AUTOSAR XML (schema 00049)
# Copyright (c) 2018 Vector Informatik GmbH.
standard types defined: boolean, uint8
package /VehicleProject
  system System
package /TP
  lin tp config LIN00: communication-cluster=LIN00
    tp address TA_0x0001: tp-address=1
    tp address TA_0x0006: tp-address=6
    tp address TA_0x007E: tp-address=126
    tp-connections:
      data-pdu=MasterReq_Tp, lin-tp-n-sdu=MasterReq, multicast=TA_0x007E, receiver=[TN_0x0001_DWF_Left, TN_0x0006_DWF_Right], transmitter=TN_Master
      data-pdu=SlaveResp_Tp, flow-control=MasterReq_Tp, lin-tp-n-sdu=SlaveResp_DWF_Left, receiver=TN_Master, transmitter=TN_0x0001_DWF_Left
      data-pdu=SlaveResp_Tp, flow-control=MasterReq_Tp, lin-tp-n-sdu=SlaveResp_DWF_Right, receiver=TN_Master, transmitter=TN_0x0006_DWF_Right
      data-pdu=MasterReq_Tp, flow-control=SlaveResp_Tp, lin-tp-n-sdu=MasterReq_DWF_Left, receiver=TN_0x0001_DWF_Left, transmitter=TN_Master
      data-pdu=MasterReq_Tp, flow-control=SlaveResp_Tp, lin-tp-n-sdu=MasterReq_DWF_Right, receiver=TN_0x0006_DWF_Right, transmitter=TN_Master
    lin tp node TN_0x0001_DWF_Left: connector=DWF_Left/CN_LIN00, tp-address=TA_0x0001
    lin tp node TN_0x0006_DWF_Right: connector=DWF_Right/CN_LIN00, tp-address=TA_0x0006
    lin tp node TN_Master: connector=GWI/CN_LIN00
package /Cluster
  lin cluster LIN00: baudrate=19200, protocol-name=LIN, protocol-version=LIN22  # Door_minimal | /*************************************************************************************/ // // Description: LIN Description file created using Vector's DaVinci Network Designer // Created: 12 Oct 2007 10:43:53 // Author: Vector Informatik GmbH // Version: 0.1 // /*************************************************************************************/
    lin physical channel CHNL: comm-connectors=[DWF_Left/CN_LIN00, DWF_Right/CN_LIN00, GWI/CN_LIN00]
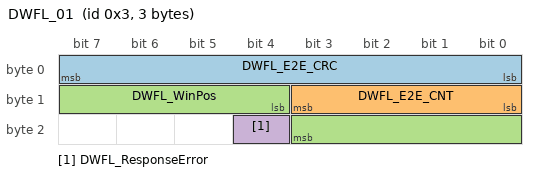
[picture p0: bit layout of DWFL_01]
      frame DWFL_01: id 0x3, from DWF_Left, to GWI, frame-length=3, lin-checksum=ENHANCED
        pdu DWFL_01: length=3, unused-bit-pattern=255
          signal DWFL_E2E_CRC: start 0, 8 bit, little-endian, i-signal-type=PRIMITIVE, init-value=0, base-type=uint8, compu {identical}, range raw 0..255, to GWI
          signal DWFL_E2E_CNT: start 8, 4 bit, little-endian, i-signal-type=PRIMITIVE, init-value=0, base-type=uint8, compu {identical}, range raw 0..15, to GWI
          signal DWFL_WinPos: start 12, 8 bit, little-endian, i-signal-type=PRIMITIVE, init-value=0, base-type=uint8, compu {identical}, range raw 0..255, to GWI
          signal DWFL_ResponseError: start 20, 1 bit, little-endian, i-signal-type=PRIMITIVE, init-value=0, base-type=boolean, compu {identical}, range raw 0..1, to GWI
          mapping SG_DWFL_E2E_SigGroup: i-signal-group=SG_DWFL_E2E_SigGroup
      frame DWFR_01: id 0x2, from DWF_Right, to GWI, frame-length=2, lin-checksum=ENHANCED
        pdu DWFR_01: length=2, unused-bit-pattern=255
          signal DWFR_WinPos: start 0, 8 bit, little-endian, i-signal-type=PRIMITIVE, init-value=0, base-type=uint8, compu {identical}, range raw 0..255, to GWI
          signal DWFR_ResponseError: start 8, 1 bit, little-endian, i-signal-type=PRIMITIVE, init-value=0, base-type=boolean, compu {identical}, range raw 0..1, to GWI
      frame GWI_01: id 0x1, from GWI, to DWF_Left DWF_Right, frame-length=1, lin-checksum=ENHANCED
        pdu GWI_01: length=1, unused-bit-pattern=255
          signal GWI_FrontWindowsRight: start 0, 2 bit, little-endian, i-signal-type=PRIMITIVE, init-value=1, base-type=uint8, compu {0=Cx0_Down, 1=Cx1_Halt, 2=Cx2_Up}, range raw 0..2, to DWF_Right
          signal GWI_FrontWindowsLeft: start 6, 2 bit, little-endian, i-signal-type=PRIMITIVE, init-value=1, base-type=uint8, compu {0=Cx0_Down, 1=Cx1_Halt, 2=Cx2_Up}, range raw 0..2, to DWF_Left
      frame MasterReq: id 0x3C, from GWI, to DWF_Left DWF_Right, frame-length=8, lin-checksum=CLASSIC
        n pdu MasterReq_Tp: length=8
      frame SlaveResp: id 0x3D, from DWF_Left DWF_Right, to GWI, frame-length=8, lin-checksum=CLASSIC
        n pdu SlaveResp_Tp: length=8
      pdu triggering PT_MasterReq: pdu=MasterReq, from GWI, to DWF_Left DWF_Right
      pdu triggering PT_MasterReq_DWF_Left: pdu=MasterReq_DWF_Left, from GWI, to DWF_Left
      pdu triggering PT_MasterReq_DWF_Right: pdu=MasterReq_DWF_Right, from GWI, to DWF_Right
      pdu triggering PT_SlaveResp_DWF_Left: pdu=SlaveResp_DWF_Left, from DWF_Left, to GWI
      pdu triggering PT_SlaveResp_DWF_Right: pdu=SlaveResp_DWF_Right, from DWF_Right, to GWI
      lin schedule table Table0: run-mode=RUN-CONTINUOUS
        table-entrys:
          delay=0.01, position-in-table=0, frame-triggering=FT_MasterReq
          delay=0.01, position-in-table=1, frame-triggering=FT_SlaveResp
      lin schedule table Table1: run-mode=RUN-CONTINUOUS
        table-entrys:
          delay=0.01, position-in-table=0, frame-triggering=FT_DWFL_01
          delay=0.01, position-in-table=1, frame-triggering=FT_DWFR_01
          delay=0.01, position-in-table=2, frame-triggering=FT_GWI_01
package /ECU
  ecu instance DWF_Left: associated-com-i-pdu-group=[DWF_Left_Rx, DWF_Left_Tx]
    lin slave CT_LIN00: protocol-version=LIN22, assign-nad=true, configured-nad=1, function-id=1, initial-nad=1, lin-error-response=ST_DWFL_ResponseError, nas-timeout=1000, supplier-id=30, variant-id=1
    lin communication connector CN_LIN00: comm-controller=DWF_Left/CT_LIN00, initial-nad=1
  ecu instance DWF_Right: associated-com-i-pdu-group=[DWF_Right_Rx, DWF_Right_Tx]
    lin slave CT_LIN00: protocol-version=LIN21, assign-nad=true, configured-nad=6, function-id=1, initial-nad=6, lin-error-response=ST_DWFR_ResponseError, nas-timeout=1000, supplier-id=30, variant-id=1
    lin communication connector CN_LIN00: comm-controller=DWF_Right/CT_LIN00, initial-nad=6, lin-ordered-configurable-frames=[{frame=DWFR_01, index=0}, {frame=GWI_01, index=1}]
  ecu instance GWI: associated-com-i-pdu-group=[GWI_Rx, GWI_Tx]
    lin master CT_LIN00: protocol-version=LIN22, time-base=0.001, time-base-jitter=0
    lin communication connector CN_LIN00: comm-controller=CT_LIN00
package /IPDUGroup
  6 x i signal i pdu group:
    DWF_Left_Rx: communication-direction=IN, i-signal-i-pdus=GWI_01
    DWF_Left_Tx: communication-direction=OUT, i-signal-i-pdus=DWFL_01
    DWF_Right_Rx: communication-direction=IN, i-signal-i-pdus=GWI_01
    DWF_Right_Tx: communication-direction=OUT, i-signal-i-pdus=DWFR_01
    GWI_Rx: communication-direction=IN, i-signal-i-pdus=[DWFL_01, DWFR_01]
    GWI_Tx: communication-direction=OUT, i-signal-i-pdus=GWI_01
package /PDU
  dcm i pdu MasterReq_DWF_Left: length=8, diag-pdu-type=DIAG-REQUEST
  dcm i pdu MasterReq_DWF_Right: length=8, diag-pdu-type=DIAG-REQUEST
  dcm i pdu MasterReq: length=8, diag-pdu-type=DIAG-REQUEST
  dcm i pdu SlaveResp_DWF_Left: length=8, diag-pdu-type=DIAG-RESPONSE
  dcm i pdu SlaveResp_DWF_Right: length=8, diag-pdu-type=DIAG-RESPONSE
package /ISignal
  i signal group SG_DWFL_E2E_SigGroup: com-based-signal-group-transformations=DT_E2E_PROFILE_02, i-signal=[DWFL_E2E_CNT, DWFL_E2E_CRC, DWFL_ResponseError, DWFL_WinPos], system-signal-group=SG_DWFL_E2E_SigGroup, end-to-end-transformation-i-signal-props{transformer=TT_E2E_PROFILE_02, data-ids=[71, 82, 83, 91, 92, 93, 94, 95, 96, 97, 98, 99, 77, 78, 79, 80], data-length=64}
package /DataTransformations
  data transformation set DataTransformationSet
    data transformation DT_E2E_PROFILE_02: execute-despite-data-unavailability=true, transformer-chain=[TT_ComBased, TT_E2E_PROFILE_02]
    transformation technology TT_ComBased: protocol=COMBased, transformer-class=SERIALIZER, version=1.0.0
    transformation technology TT_E2E_PROFILE_02:
      buffer-properties={buffer-computation=compu-rational-coeffs={compu-numerator=[0, 1], compu-denominator=1}, header-length=0, in-place=1}
      has-internal-state=true
      needs-original-data=false
      protocol=E2E
      end-to-end-transformation-description{counter-offset=8, crc-offset=0, data-id-mode=ALTERNATING-8-BIT, data-id-nibble-offset=0, max-delta-counter=2, max-error-state-init=1, max-error-state-invalid=1, max-error-state-valid=15, max-no-new-or-repeated-data=15, min-ok-state-init=1, min-ok-state-invalid=3, min-ok-state-valid=1, offset=0, profile-name=PROFILE_02, sync-counter-init=1, upper-header-bits-to-shift=0, window-size=255}
      transformer-class=SAFETY
      version=1.0.0
package /Signal
  16 x system signal, all with compu {identical}, range raw 0..255:
    MasterReqB{0..7}
    SlaveRespB{0..7}
  system signal group SG_DWFL_E2E_SigGroup: system-signal=[DWFL_E2E_CNT, DWFL_E2E_CRC, DWFL_ResponseError, DWFL_WinPos]  # Extension signal group
